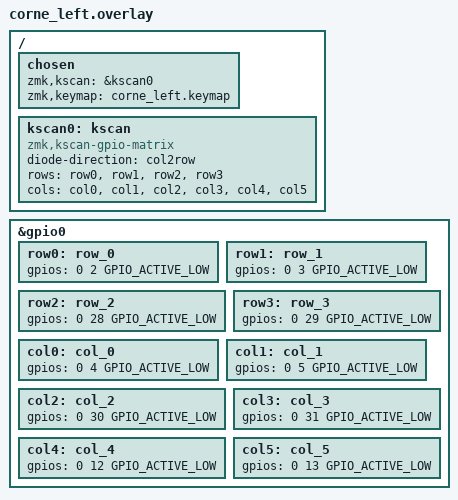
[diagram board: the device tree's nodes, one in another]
/ {
    chosen {
        zmk,kscan = &kscan0;
        zmk,keymap = "corne_left.keymap";
    };

    kscan0: kscan {
        compatible = "zmk,kscan-gpio-matrix";
        diode-direction = "col2row";   // Corne default
        rows = <&row0 &row1 &row2 &row3>;
        cols = <&col0 &col1 &col2 &col3 &col4 &col5>;
    };
};

&gpio0 {
    row0: row_0 { gpios = <0 2 GPIO_ACTIVE_LOW>; };   // Pin 1
    row1: row_1 { gpios = <0 3 GPIO_ACTIVE_LOW>; };   // Pin 2
    row2: row_2 { gpios = <0 28 GPIO_ACTIVE_LOW>; };  // Pin 3
    row3: row_3 { gpios = <0 29 GPIO_ACTIVE_LOW>; };  // Pin 4

    col0: col_0 { gpios = <0 4 GPIO_ACTIVE_LOW>; };   // Pin 5
    col1: col_1 { gpios = <0 5 GPIO_ACTIVE_LOW>; };   // Pin 6
    col2: col_2 { gpios = <0 30 GPIO_ACTIVE_LOW>; };  // Pin 7
    col3: col_3 { gpios = <0 31 GPIO_ACTIVE_LOW>; };  // Pin 8
    col4: col_4 { gpios = <0 12 GPIO_ACTIVE_LOW>; };  // Pin 9
    col5: col_5 { gpios = <0 13 GPIO_ACTIVE_LOW>; };  // Pin 10
};
